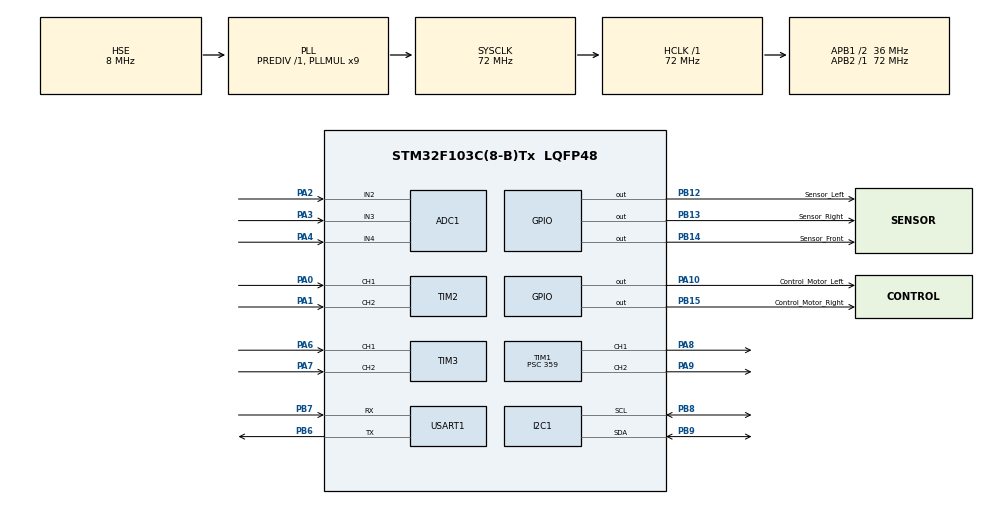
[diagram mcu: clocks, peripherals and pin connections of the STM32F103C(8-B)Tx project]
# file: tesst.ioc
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ADC1.Channel-4\#ChannelRegularConversion=ADC_CHANNEL_2
ADC1.Channel-5\#ChannelRegularConversion=ADC_CHANNEL_3
ADC1.Channel-6\#ChannelRegularConversion=ADC_CHANNEL_4
ADC1.NbrOfConversion=3
ADC1.NbrOfConversionFlag=1
ADC1.Rank-4\#ChannelRegularConversion=1
ADC1.Rank-5\#ChannelRegularConversion=2
ADC1.Rank-6\#ChannelRegularConversion=3
ADC1.SamplingTime-4\#ChannelRegularConversion=ADC_SAMPLETIME_239CYCLES_5
ADC1.SamplingTime-5\#ChannelRegularConversion=ADC_SAMPLETIME_239CYCLES_5
ADC1.SamplingTime-6\#ChannelRegularConversion=ADC_SAMPLETIME_239CYCLES_5
ADC1.master=1
Dma.Request0=USART1_TX
Dma.USART1_TX.0.Direction=DMA_MEMORY_TO_PERIPH
Dma.USART1_TX.0.Instance=DMA1_Channel4
Dma.USART1_TX.0.MemDataAlignment=DMA_MDATAALIGN_BYTE
Dma.USART1_TX.0.MemInc=DMA_MINC_ENABLE
Dma.USART1_TX.0.Mode=DMA_NORMAL
Dma.USART1_TX.0.PeriphDataAlignment=DMA_PDATAALIGN_BYTE
Dma.USART1_TX.0.PeriphInc=DMA_PINC_DISABLE
Dma.USART1_TX.0.Priority=DMA_PRIORITY_LOW
Mcu.Family=STM32F1
Mcu.Name=STM32F103C(8-B)Tx
Mcu.Package=LQFP48
NVIC.DMA1_Channel4_IRQn=true\:0\:0\:false\:false\:true\:false\:true\:true
NVIC.PriorityGroup=NVIC_PRIORITYGROUP_4
NVIC.TIM4_IRQn=true\:0\:0\:false\:false\:true\:true\:true\:true
PA0-WKUP.Signal=S_TIM2_CH1_ETR
PA1.Signal=S_TIM2_CH2
PA10.GPIO_Label=Control_Motor_Left
PA10.GPIO_PuPd=GPIO_PULLUP
PA10.GPIO_Speed=GPIO_SPEED_FREQ_HIGH
PA10.PinState=GPIO_PIN_SET
PA10.Signal=GPIO_Output
PA13.Mode=Serial_Wire
PA13.Signal=SYS_JTMS-SWDIO
PA14.Mode=Serial_Wire
PA14.Signal=SYS_JTCK-SWCLK
PA2.Signal=ADCx_IN2
PA3.Signal=ADCx_IN3
PA4.Signal=ADCx_IN4
PA6.Signal=S_TIM3_CH1
PA7.Signal=S_TIM3_CH2
PA8.Signal=S_TIM1_CH1
PA9.Signal=S_TIM1_CH2
PB12.GPIO_Label=Sensor_Left
PB12.GPIO_ModeDefaultOutputPP=GPIO_MODE_OUTPUT_PP
PB12.GPIO_PuPd=GPIO_PULLUP
PB12.GPIO_Speed=GPIO_SPEED_FREQ_HIGH
PB12.PinState=GPIO_PIN_RESET
PB12.Signal=GPIO_Output
PB13.GPIO_Label=Sensor_Right
PB13.GPIO_ModeDefaultOutputPP=GPIO_MODE_OUTPUT_PP
PB13.GPIO_PuPd=GPIO_PULLUP
PB13.GPIO_Speed=GPIO_SPEED_FREQ_HIGH
PB13.PinState=GPIO_PIN_RESET
PB13.Signal=GPIO_Output
PB14.GPIO_Label=Sensor_Front
PB14.GPIO_ModeDefaultOutputPP=GPIO_MODE_OUTPUT_PP
PB14.GPIO_PuPd=GPIO_PULLUP
PB14.GPIO_Speed=GPIO_SPEED_FREQ_HIGH
PB14.PinState=GPIO_PIN_RESET
PB14.Signal=GPIO_Output
PB15.GPIO_Label=Control_Motor_Right
PB15.GPIO_PuPd=GPIO_PULLUP
PB15.GPIO_Speed=GPIO_SPEED_FREQ_HIGH
PB15.PinState=GPIO_PIN_SET
PB15.Signal=GPIO_Output
PB6.Mode=Asynchronous
PB6.Signal=USART1_TX
PB7.Mode=Asynchronous
PB7.Signal=USART1_RX
PB8.Mode=I2C
PB8.Signal=I2C1_SCL
PB9.Mode=I2C
PB9.Signal=I2C1_SDA
PD0-OSC_IN.Mode=HSE-External-Oscillator
PD0-OSC_IN.Signal=RCC_OSC_IN
PD1-OSC_OUT.Mode=HSE-External-Oscillator
PD1-OSC_OUT.Signal=RCC_OSC_OUT
ProjectManager.HeapSize=0x200
ProjectManager.StackSize=0x400
ProjectManager.TargetToolchain=MDK-ARM V5
RCC.ADCPresc=RCC_ADCPCLK2_DIV6
RCC.AHBFreq_Value=72000000
RCC.APB1CLKDivider=RCC_HCLK_DIV2
RCC.APB1Freq_Value=36000000
RCC.APB1TimFreq_Value=72000000
RCC.APB2Freq_Value=72000000
RCC.APB2TimFreq_Value=72000000
RCC.HCLKFreq_Value=72000000
RCC.PLLMUL=RCC_PLL_MUL9
RCC.PLLSourceVirtual=RCC_PLLSOURCE_HSE
RCC.SYSCLKFreq_VALUE=72000000
RCC.SYSCLKSource=RCC_SYSCLKSOURCE_PLLCLK
RCC.USBFreq_Value=72000000
SH.ADCx_IN2.0=ADC1_IN2,IN2
SH.ADCx_IN3.0=ADC1_IN3,IN3
SH.ADCx_IN4.0=ADC1_IN4,IN4
SH.S_TIM1_CH1.0=TIM1_CH1,PWM Generation1 CH1
SH.S_TIM1_CH2.0=TIM1_CH2,PWM Generation2 CH2
SH.S_TIM2_CH1_ETR.0=TIM2_CH1,Encoder_Interface
SH.S_TIM2_CH2.0=TIM2_CH2,Encoder_Interface
SH.S_TIM3_CH1.0=TIM3_CH1,Encoder_Interface
SH.S_TIM3_CH2.0=TIM3_CH2,Encoder_Interface
TIM1.AutoReloadPreload=TIM_AUTORELOAD_PRELOAD_ENABLE
TIM1.Channel-PWM\ Generation1\ CH1=TIM_CHANNEL_1
TIM1.Channel-PWM\ Generation2\ CH2=TIM_CHANNEL_2
TIM1.Period=99
TIM1.Prescaler=359
TIM2.EncoderMode=TIM_ENCODERMODE_TI12
TIM2.IC1Filter=10
TIM2.IC2Filter=10
TIM3.EncoderMode=TIM_ENCODERMODE_TI12
TIM3.IC1Filter=10
TIM3.IC2Filter=10
TIM4.AutoReloadPreload=TIM_AUTORELOAD_PRELOAD_ENABLE
TIM4.Period=99
TIM4.Prescaler=719
USART1.VirtualMode=VM_ASYNC
VP_TIM1_VS_ClockSourceINT.Mode=Internal
VP_TIM4_VS_ClockSourceINT.Mode=Internal
board=custom

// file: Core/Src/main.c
/* USER CODE BEGIN Header */
/**
  ******************************************************************************
  * @file           : main.c
  * @brief          : Main program body
  ******************************************************************************
  * @attention
  *
  * Copyright (c) 2024 STMicroelectronics.
  * All rights reserved.
  *
  * This software is licensed under terms that can be found in the LICENSE file
  * in the root directory of this software component.
  * If no LICENSE file comes with this software, it is provided AS-IS.
  *
  ******************************************************************************
  */
/* USER CODE END Header */
#include "main.h"
#include "adc.h"
#include "dma.h"
#include "i2c.h"
#include "tim.h"
#include "usart.h"
#include "gpio.h"

/* USER CODE BEGIN PV */
static uint16_t u16_BufferADC[4];
/* USER CODE END PV */

void SystemClock_Config(void);

int main(void)
{

  /* MCU Configuration--------------------------------------------------------*/

  /* Reset of all peripherals, Initializes the Flash interface and the Systick. */
  HAL_Init();

  /* Configure the system clock */
  SystemClock_Config();

  /* Initialize all configured peripherals */
  MX_GPIO_Init();
  MX_DMA_Init();
  MX_ADC1_Init();
  MX_I2C1_Init();
  MX_TIM1_Init();
  MX_TIM2_Init();
  MX_TIM3_Init();
  MX_TIM4_Init();
  MX_USART1_UART_Init();
  /* USER CODE BEGIN 2 */
	// Start pwm timer 1, channel 1
  HAL_TIM_PWM_Start(&htim1, TIM_CHANNEL_1);

  // Start pwm timer 1, channel 2
  HAL_TIM_PWM_Start(&htim1, TIM_CHANNEL_2);

  // Start interrupt timer 4
  HAL_TIM_Base_Start_IT(&htim4);

  // Start Read TIM Encoder 2,
  HAL_TIM_Encoder_Start(&htim2, TIM_CHANNEL_ALL);

  // Start Read TIM Encoder 3.
  HAL_TIM_Encoder_Start(&htim3, TIM_CHANNEL_ALL);
  /* USER CODE END 2 */

  /* Infinite loop */
  while (1)
  {

    /* USER CODE BEGIN 3 */
	  HAL_Delay(100);
  }
  /* USER CODE END 3 */
}

void SystemClock_Config(void)
{
  RCC_OscInitTypeDef RCC_OscInitStruct = {0};
  RCC_ClkInitTypeDef RCC_ClkInitStruct = {0};
  RCC_PeriphCLKInitTypeDef PeriphClkInit = {0};

  /** Initializes the RCC Oscillators according to the specified parameters
  * in the RCC_OscInitTypeDef structure.
  */
  RCC_OscInitStruct.OscillatorType = RCC_OSCILLATORTYPE_HSE;
  RCC_OscInitStruct.HSEState = RCC_HSE_ON;
  RCC_OscInitStruct.HSEPredivValue = RCC_HSE_PREDIV_DIV1;
  RCC_OscInitStruct.HSIState = RCC_HSI_ON;
  RCC_OscInitStruct.PLL.PLLState = RCC_PLL_ON;
  RCC_OscInitStruct.PLL.PLLSource = RCC_PLLSOURCE_HSE;
  RCC_OscInitStruct.PLL.PLLMUL = RCC_PLL_MUL9;
  if (HAL_RCC_OscConfig(&RCC_OscInitStruct) != HAL_OK)
  {
    Error_Handler();
  }

  /** Initializes the CPU, AHB and APB buses clocks
  */
  RCC_ClkInitStruct.ClockType = RCC_CLOCKTYPE_HCLK|RCC_CLOCKTYPE_SYSCLK
                              |RCC_CLOCKTYPE_PCLK1|RCC_CLOCKTYPE_PCLK2;
  RCC_ClkInitStruct.SYSCLKSource = RCC_SYSCLKSOURCE_PLLCLK;
  RCC_ClkInitStruct.AHBCLKDivider = RCC_SYSCLK_DIV1;
  RCC_ClkInitStruct.APB1CLKDivider = RCC_HCLK_DIV2;
  RCC_ClkInitStruct.APB2CLKDivider = RCC_HCLK_DIV1;

  if (HAL_RCC_ClockConfig(&RCC_ClkInitStruct, FLASH_LATENCY_2) != HAL_OK)
  {
    Error_Handler();
  }
  PeriphClkInit.PeriphClockSelection = RCC_PERIPHCLK_ADC;
  PeriphClkInit.AdcClockSelection = RCC_ADCPCLK2_DIV6;
  if (HAL_RCCEx_PeriphCLKConfig(&PeriphClkInit) != HAL_OK)
  {
    Error_Handler();
  }
}

void Error_Handler(void)
{
  __disable_irq();
  while (1)
  {
  }
}
